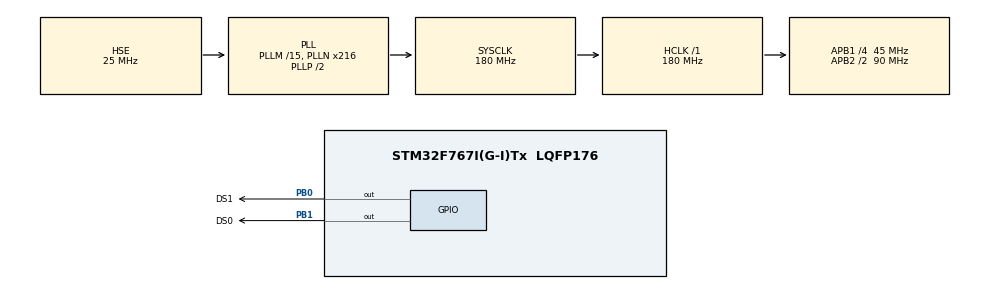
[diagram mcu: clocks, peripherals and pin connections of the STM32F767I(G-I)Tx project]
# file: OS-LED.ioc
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FREERTOS.Tasks01=defaultTask,24,128,StartDefaultTask,Default,NULL,Dynamic,NULL,NULL;LEDTask,8,128,StartLEDTask,Default,NULL,Dynamic,NULL,NULL
Mcu.Family=STM32F7
Mcu.Name=STM32F767I(G-I)Tx
Mcu.Package=LQFP176
NVIC.PriorityGroup=NVIC_PRIORITYGROUP_4
NVIC.TIM1_UP_TIM10_IRQn=true\:0\:0\:false\:false\:true\:false\:false\:true
NVIC.TimeBase=TIM1_UP_TIM10_IRQn
NVIC.TimeBaseIP=TIM1
PA13.Mode=Trace_Asynchronous_SW
PA13.Signal=SYS_JTMS-SWDIO
PA14.Mode=Trace_Asynchronous_SW
PA14.Signal=SYS_JTCK-SWCLK
PB0.GPIO_Label=DS1
PB0.Signal=GPIO_Output
PB1.GPIO_Label=DS0
PB1.Signal=GPIO_Output
PB3.Mode=Trace_Asynchronous_SW
PB3.Signal=SYS_JTDO-SWO
PC14/OSC32_IN.Mode=LSE-External-Oscillator
PC14/OSC32_IN.Signal=RCC_OSC32_IN
PC15/OSC32_OUT.Mode=LSE-External-Oscillator
PC15/OSC32_OUT.Signal=RCC_OSC32_OUT
PH0/OSC_IN.Mode=HSE-External-Oscillator
PH0/OSC_IN.Signal=RCC_OSC_IN
PH1/OSC_OUT.Mode=HSE-External-Oscillator
PH1/OSC_OUT.Signal=RCC_OSC_OUT
ProjectManager.HeapSize=0x200
ProjectManager.StackSize=0x400
ProjectManager.TargetToolchain=STM32CubeIDE
RCC.AHBFreq_Value=180000000
RCC.APB1CLKDivider=RCC_HCLK_DIV4
RCC.APB1Freq_Value=45000000
RCC.APB1TimFreq_Value=90000000
RCC.APB2CLKDivider=RCC_HCLK_DIV2
RCC.APB2Freq_Value=90000000
RCC.APB2TimFreq_Value=180000000
RCC.CortexFreq_Value=180000000
RCC.HCLKFreq_Value=180000000
RCC.HSE_VALUE=25000000
RCC.HSI_VALUE=16000000
RCC.PLLM=15
RCC.PLLN=216
RCC.PLLSourceVirtual=RCC_PLLSOURCE_HSE
RCC.SYSCLKFreq_VALUE=180000000
RCC.SYSCLKSource=RCC_SYSCLKSOURCE_PLLCLK
RCC.USBFreq_Value=180000000
RCC.VCOOutputFreq_Value=360000000
VP_FREERTOS_VS_CMSIS_V2.Mode=CMSIS_V2
VP_SYS_VS_tim1.Mode=TIM1
board=custom

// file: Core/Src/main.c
/* USER CODE BEGIN Header */
/**
  ******************************************************************************
  * @file           : main.c
  * @brief          : Main program body
  ******************************************************************************
  * @attention
  *
  * <h2><center>&copy; Copyright (c) 2021 STMicroelectronics.
  * All rights reserved.</center></h2>
  *
  * This software component is licensed by ST under Ultimate Liberty license
  * SLA0044, the "License"; You may not use this file except in compliance with
  * the License. You may obtain a copy of the License at:
  *                             www.st.com/SLA0044
  *
  ******************************************************************************
  */
/* USER CODE END Header */
#include "main.h"
#include "cmsis_os.h"
#include "gpio.h"

void SystemClock_Config(void);
void MX_FREERTOS_Init(void);

/* USER CODE BEGIN 0 */
int _write(int file, char *ptr, int len)
{
	int i = 0;
	for(i = 0; i < len; i++)
		ITM_SendChar((*ptr++));

	return len;
}
/* USER CODE END 0 */

int main(void)
{

  /* MCU Configuration--------------------------------------------------------*/

  /* Reset of all peripherals, Initializes the Flash interface and the Systick. */
  HAL_Init();

  /* Configure the system clock */
  SystemClock_Config();

  /* Initialize all configured peripherals */
  MX_GPIO_Init();

  /* Init scheduler */
  osKernelInitialize();  /* Call init function for freertos objects (in freertos.c) */
  MX_FREERTOS_Init();
  /* Start scheduler */
  osKernelStart();

  /* We should never get here as control is now taken by the scheduler */
  /* Infinite loop */
  while (1)
  {

  }
}

void SystemClock_Config(void)
{
  RCC_OscInitTypeDef RCC_OscInitStruct = {0};
  RCC_ClkInitTypeDef RCC_ClkInitStruct = {0};

  /** Configure LSE Drive Capability
  */
  HAL_PWR_EnableBkUpAccess();
  /** Configure the main internal regulator output voltage
  */
  __HAL_RCC_PWR_CLK_ENABLE();
  __HAL_PWR_VOLTAGESCALING_CONFIG(PWR_REGULATOR_VOLTAGE_SCALE1);
  /** Initializes the RCC Oscillators according to the specified parameters
  * in the RCC_OscInitTypeDef structure.
  */
  RCC_OscInitStruct.OscillatorType = RCC_OSCILLATORTYPE_HSE;
  RCC_OscInitStruct.HSEState = RCC_HSE_ON;
  RCC_OscInitStruct.PLL.PLLState = RCC_PLL_ON;
  RCC_OscInitStruct.PLL.PLLSource = RCC_PLLSOURCE_HSE;
  RCC_OscInitStruct.PLL.PLLM = 15;
  RCC_OscInitStruct.PLL.PLLN = 216;
  RCC_OscInitStruct.PLL.PLLP = RCC_PLLP_DIV2;
  RCC_OscInitStruct.PLL.PLLQ = 2;
  if (HAL_RCC_OscConfig(&RCC_OscInitStruct) != HAL_OK)
  {
    Error_Handler();
  }
  /** Initializes the CPU, AHB and APB buses clocks
  */
  RCC_ClkInitStruct.ClockType = RCC_CLOCKTYPE_HCLK|RCC_CLOCKTYPE_SYSCLK
                              |RCC_CLOCKTYPE_PCLK1|RCC_CLOCKTYPE_PCLK2;
  RCC_ClkInitStruct.SYSCLKSource = RCC_SYSCLKSOURCE_PLLCLK;
  RCC_ClkInitStruct.AHBCLKDivider = RCC_SYSCLK_DIV1;
  RCC_ClkInitStruct.APB1CLKDivider = RCC_HCLK_DIV4;
  RCC_ClkInitStruct.APB2CLKDivider = RCC_HCLK_DIV2;

  if (HAL_RCC_ClockConfig(&RCC_ClkInitStruct, FLASH_LATENCY_5) != HAL_OK)
  {
    Error_Handler();
  }
}

 /**
  * @brief  Period elapsed callback in non blocking mode
  * @note   This function is called  when TIM1 interrupt took place, inside
  * HAL_TIM_IRQHandler(). It makes a direct call to HAL_IncTick() to increment
  * a global variable "uwTick" used as application time base.
  * @param  htim : TIM handle
  * @retval None
  */
void HAL_TIM_PeriodElapsedCallback(TIM_HandleTypeDef *htim)
{
  if (htim->Instance == TIM1) {
    HAL_IncTick();
  }
}

void Error_Handler(void)
{
  __disable_irq();
  while (1)
  {
  }
}

/************************ (C) COPYRIGHT STMicroelectronics *****END OF FILE****/

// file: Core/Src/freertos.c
/* USER CODE BEGIN Header */
/**
  ******************************************************************************
  * File Name          : freertos.c
  * Description        : Code for freertos applications
  ******************************************************************************
  * @attention
  *
  * <h2><center>&copy; Copyright (c) 2021 STMicroelectronics.
  * All rights reserved.</center></h2>
  *
  * This software component is licensed by ST under Ultimate Liberty license
  * SLA0044, the "License"; You may not use this file except in compliance with
  * the License. You may obtain a copy of the License at:
  *                             www.st.com/SLA0044
  *
  ******************************************************************************
  */
/* USER CODE END Header */

#include "FreeRTOS.h"
#include "task.h"
#include "main.h"
#include "cmsis_os.h"

/* USER CODE BEGIN Includes */
#include <stdio.h>
/* USER CODE END Includes */

/* Definitions for defaultTask */
osThreadId_t defaultTaskHandle;
const osThreadAttr_t defaultTask_attributes = {
  .name = "defaultTask",
  .stack_size = 128 * 4,
  .priority = (osPriority_t) osPriorityNormal,
};
/* Definitions for LEDTask */
osThreadId_t LEDTaskHandle;
const osThreadAttr_t LEDTask_attributes = {
  .name = "LEDTask",
  .stack_size = 128 * 4,
  .priority = (osPriority_t) osPriorityLow,
};

void StartDefaultTask(void *argument);
void StartLEDTask(void *argument);

void MX_FREERTOS_Init(void); /* (MISRA C 2004 rule 8.1) */

void MX_FREERTOS_Init(void) {

  /* Create the thread(s) */
  /* creation of defaultTask */
  defaultTaskHandle = osThreadNew(StartDefaultTask, NULL, &defaultTask_attributes);

  /* creation of LEDTask */
  LEDTaskHandle = osThreadNew(StartLEDTask, NULL, &LEDTask_attributes);

}

void StartDefaultTask(void *argument)
{
  for(;;)
  {
    osDelay(1);
  }
}

void StartLEDTask(void *argument)
{
  /* USER CODE BEGIN StartLEDTask */
  /* Infinite loop */
  for(;;)
  {
	  HAL_GPIO_TogglePin(DS0_GPIO_Port, DS0_Pin);
	  osDelay(100);
    HAL_GPIO_TogglePin(DS1_GPIO_Port, DS1_Pin);
    osDelay(50);

	  printf("csy freertos swo hello world.\n");
  }
  /* USER CODE END StartLEDTask */
}

/************************ (C) COPYRIGHT STMicroelectronics *****END OF FILE****/
